AUTOSAR XML (schema 4-2-2)
package /AUTOSAR_BswM/SwComponentTypes
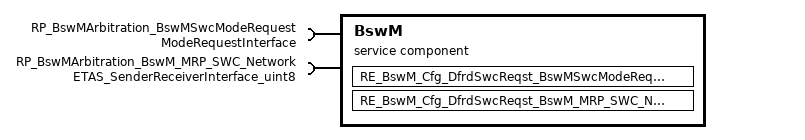
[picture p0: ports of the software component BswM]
  service sw component type BswM
    require port RP_BswMArbitration_BswMSwcModeRequest: required-interface=ModeRequestInterface
    require port RP_BswMArbitration_BswM_MRP_SWC_Network: required-interface=ETAS_SenderReceiverInterface_uint8
    behavior IB_BswM: data-type-mapping=[ECUM_STATE_Mapping, AppMode_Mapping, ComMModeMapping, DTS_DcmEcuReset, DTS_DcmDiagnosticSessionControl]
      data received event DRE_BswM_Cfg_DfrdSwcReqst_BswMSwcModeRequest: start-on-event=RE_BswM_Cfg_DfrdSwcReqst_BswMSwcModeRequest, data=RP_BswMArbitration_BswMSwcModeRequest.AppMode
      data received event DRE_BswM_Cfg_DfrdSwcReqst_BswM_MRP_SWC_Network: start-on-event=RE_BswM_Cfg_DfrdSwcReqst_BswM_MRP_SWC_Network, data=RP_BswMArbitration_BswM_MRP_SWC_Network.uint8
      runnable RE_BswM_Cfg_DfrdSwcReqst_BswMSwcModeRequest: can-be-invoked-concurrently=true, symbol=BswM_Cfg_DfrdSwcReqst_BswMSwcModeRequest
        data-receive-point-by-arguments:
          access DRP_BswMSwcModeRequest: accessed-variable=RP_BswMArbitration_BswMSwcModeRequest.AppMode
      runnable RE_BswM_Cfg_DfrdSwcReqst_BswM_MRP_SWC_Network: can-be-invoked-concurrently=true, symbol=BswM_Cfg_DfrdSwcReqst_BswM_MRP_SWC_Network
        data-receive-point-by-arguments:
          access DRP_BswM_MRP_SWC_Network: accessed-variable=RP_BswMArbitration_BswM_MRP_SWC_Network.uint8
package /AUTOSAR_BswM/SwcImplementations
  swc implementation SWCIMPL_BswM: programming-language=C, sw-version=1.0.0, swc-bsw-mapping=BswM, behavior=IB_BswM
    code-descriptors:
      code CodeDescriptor: artifact-descriptors=autosar-engineering-object={short-label=ArEngObj, category=SWSRC}
package /AUTOSAR_BswM/SwcBswMappings
  swc bsw mapping BswM: bsw-behavior=IB_BswM, swc-behavior=IB_BswM
